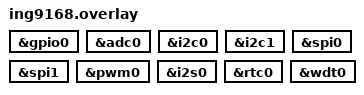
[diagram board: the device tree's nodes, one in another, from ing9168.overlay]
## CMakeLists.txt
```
cmake_minimum_required(VERSION 3.20.0)
find_package(Zephyr REQUIRED HINTS $ENV{ZEPHYR_BASE})
project(ingchips_driver_build_all)
target_sources(app PRIVATE src/main.c)
```

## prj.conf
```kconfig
CONFIG_SERIAL=y
CONFIG_GPIO=y
CONFIG_ADC=y
CONFIG_I2C=y
CONFIG_SPI=y
CONFIG_PWM=y
CONFIG_I2S=y
CONFIG_COUNTER=y
CONFIG_WATCHDOG=y
CONFIG_MAIN_STACK_SIZE=1024
```

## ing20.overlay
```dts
&gpio0 { status = "okay"; };
&adc0 { status = "okay"; };
&i2c0 { status = "okay"; };
&spi0 { status = "okay"; };
&spi1 { status = "okay"; };
&pwm0 { status = "okay"; };
&i2s0 { status = "okay"; };
&rtc0 { status = "okay"; };
&wdt0 { status = "okay"; };
```

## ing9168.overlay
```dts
&gpio0 { status = "okay"; };
&adc0 { status = "okay"; };
&i2c0 { status = "okay"; };
&i2c1 { status = "okay"; };
&spi0 { status = "okay"; };
&spi1 { status = "okay"; };
&pwm0 { status = "okay"; };
&i2s0 { status = "okay"; };
&rtc0 { status = "okay"; };
&wdt0 { status = "okay"; };
```

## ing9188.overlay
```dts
&gpio0 { status = "okay"; };
&i2c0 { status = "okay"; };
&i2c1 { status = "okay"; };
&spi0 { status = "okay"; };
&spi1 { status = "okay"; };
&pwm0 { status = "okay"; };
&rtc0 { status = "okay"; };
&wdt0 { status = "okay"; };
```

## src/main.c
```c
/* SPDX-License-Identifier: Apache-2.0 */
#include <zephyr/kernel.h>

int main(void)
{
	return 0;
}
```
